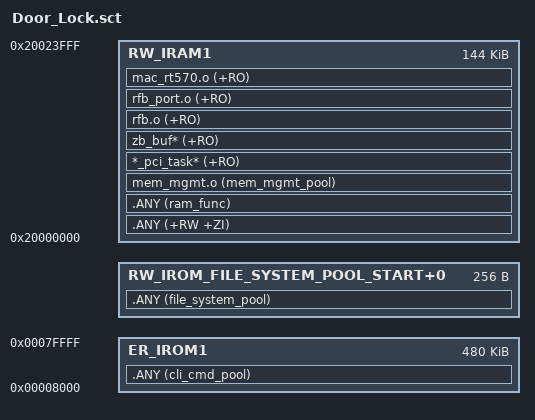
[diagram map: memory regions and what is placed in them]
; *************************************************************
; *** Scatter-Loading Description File generated by uVision ***
; *************************************************************

LR_IROM1 0x00008000 0x00078000  {    ; load region size_region
  ER_IROM1 0x00008000 0x00078000  {  ; load address = execution address
   *.o (RESET, +First)
   *(InRoot$$Sections)
   .ANY (+RO)
  }
  RW_IROM_CLI_CMD_POOL_START+0 {  ; CLI command description pool
	.ANY (cli_cmd_pool)
  }
  RW_IROM_FILE_SYSTEM_POOL_START+0 ALIGN 0x100{
	.ANY (file_system_pool)
  }
  RW_IRAM1 0x20000000 0x24000  {  ; RW data & FreeRTOS heap
   .ANY (+RW +ZI)
   .ANY (ram_func)
   mem_mgmt.o (mem_mgmt_pool)
   	*_pci_task* (+RO)
	zb_buf* (+RO)
	rfb.o (+RO)
	rfb_port.o (+RO)
	;rfb_rtos_comm_common.o (+RO)
	;rfb_rtos_comm_15p4Mac.o (+RO)
	mac_rt570.o (+RO)
  }
}
